# SGPIO5 register map
Registers from a debugger description file.
Registers are 32-bit, access not given, no defined reset value unless marked. A register's access mark holds for its fields unless they carry their own. Addresses are absolute; registers are grouped by the start of their names; lines under a group give offsets from that group; [hi:lo] are bit positions; {n}, {i} and the like mark numbered series; 'fields as' and 'values as' point back to an identical list; <NAME> marks a mode.

## SGPIO5
0x50010000 SGPIO5/Input ro
  [31:0] Input
0x50010004 SGPIO5/Output
  [31:0] Output
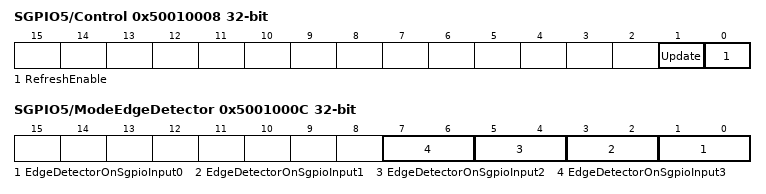
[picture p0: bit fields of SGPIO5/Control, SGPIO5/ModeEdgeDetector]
0x50010008 SGPIO5/Control
  [1] Update, [0] RefreshEnable
0x5001000C SGPIO5/ModeEdgeDetector
  [2n+1:2n] EdgeDetectorOnSgpioInput{n} (n=0..3)
0x50010010 SGPIO5/StatusInt0
  [3:0] StatusInt0
0x50010014 SGPIO5/StatusInt1
  [3:0] StatusInt1
0x50010018 SGPIO5/MaskInt
  [3:0] MaskInt
0x5001001C SGPIO5/ClearInt
  [3:0] ClearInt
